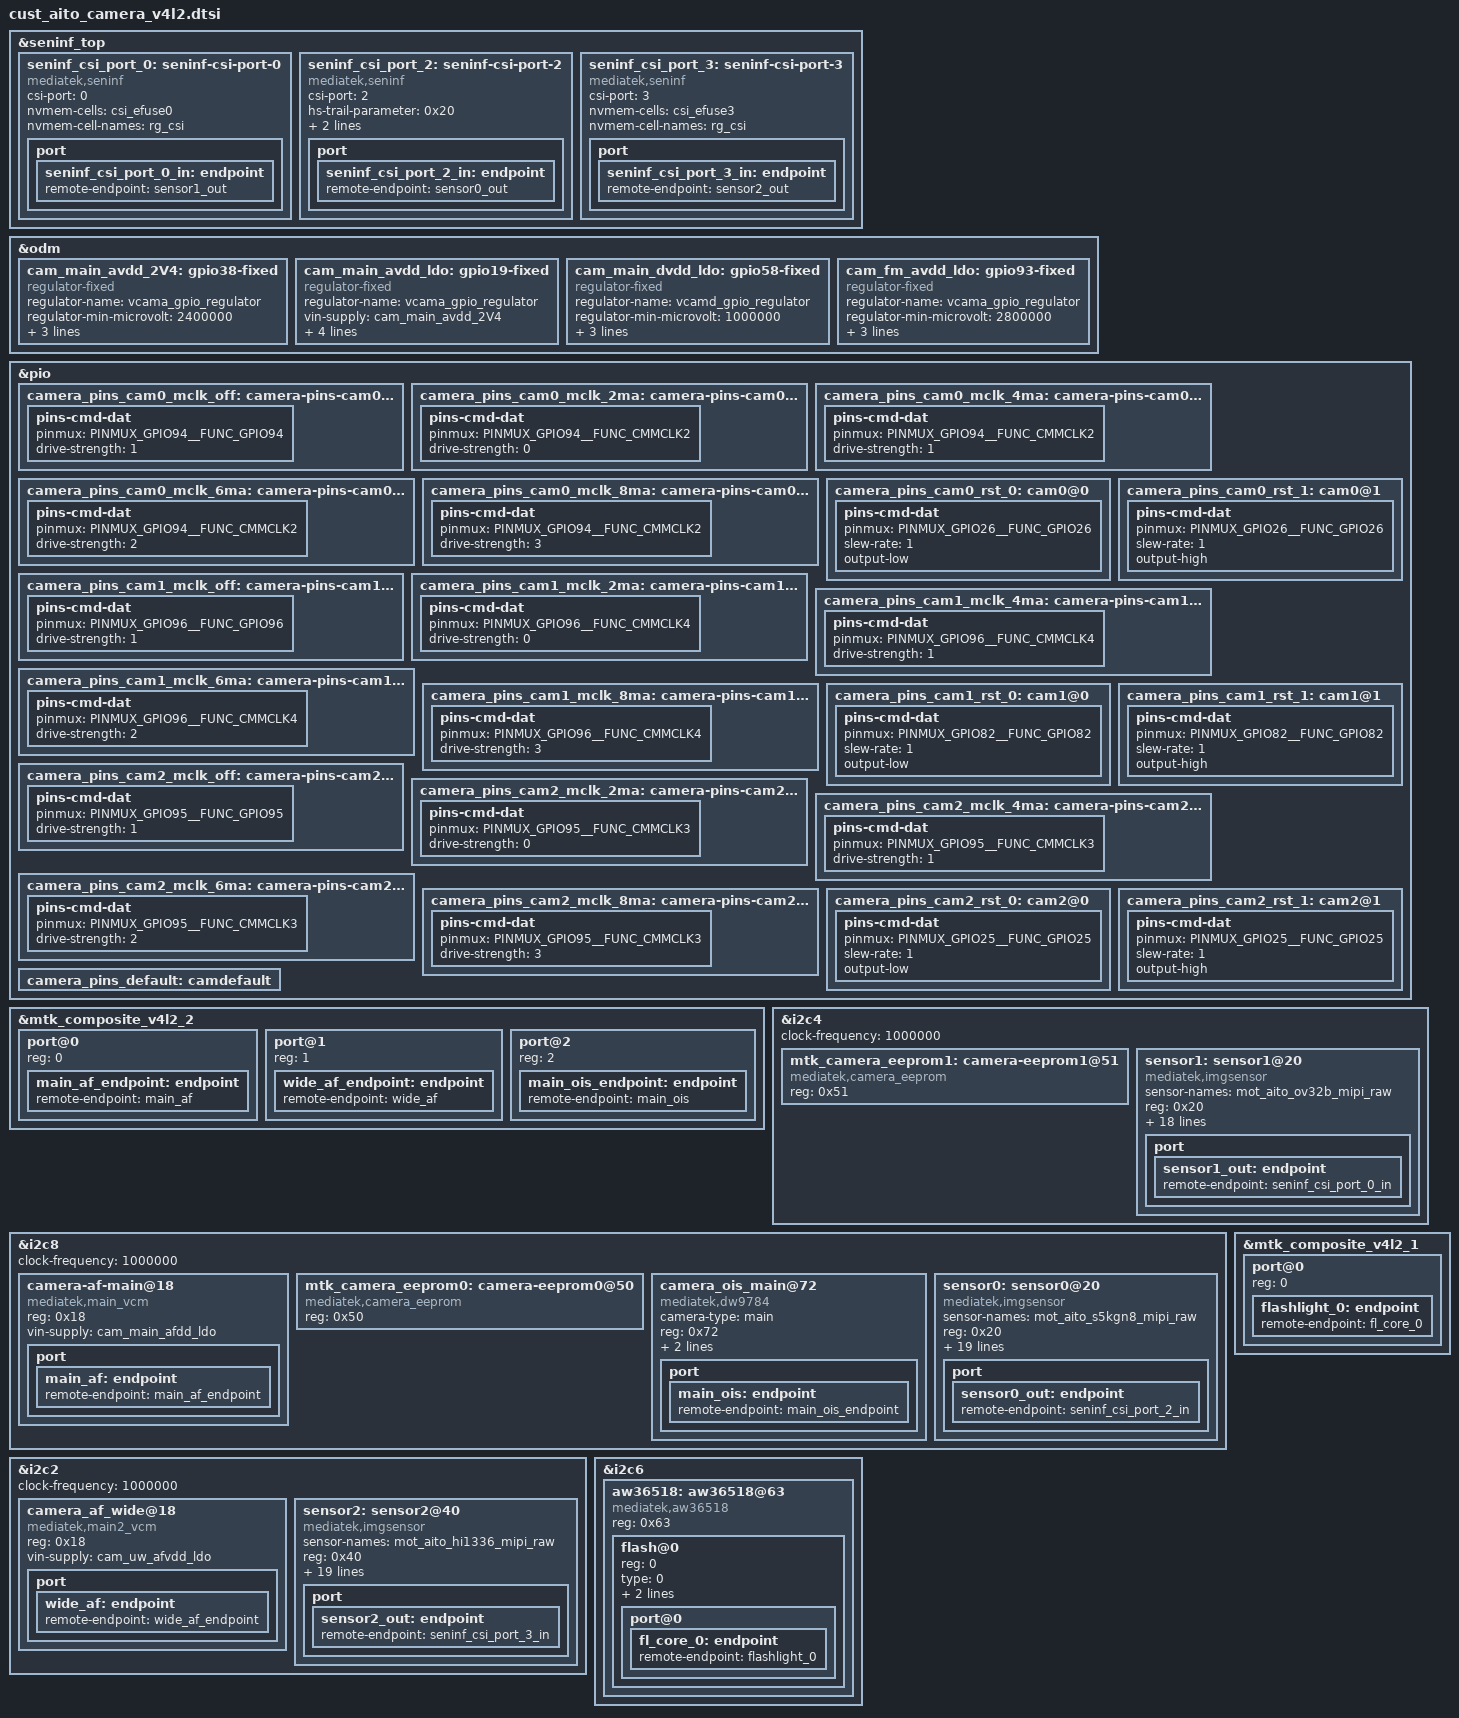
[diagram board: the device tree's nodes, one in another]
// SPDX-License-Identifier: GPL-2.0
/* Copyright (c) 2020 MediaTek Inc. */
#include <dt-bindings/clock/mt6878-clk.h>

&seninf_top {
		seninf_csi_port_0: seninf-csi-port-0 {
			compatible = "mediatek,seninf";
			csi-port = "0";
			nvmem-cells = <&csi_efuse0>;
			nvmem-cell-names = "rg_csi";
			port {
				seninf_csi_port_0_in: endpoint {
					remote-endpoint = <&sensor1_out>;
				};
			};
		};

		seninf_csi_port_2: seninf-csi-port-2 {
			compatible = "mediatek,seninf";
			csi-port = "2";
			hs-trail-parameter = <0x20>;
			nvmem-cells = <&csi_efuse2>;
			nvmem-cell-names = "rg_csi";
			port {
				seninf_csi_port_2_in: endpoint {
					remote-endpoint = <&sensor0_out>;
				};
			};
		};
		seninf_csi_port_3: seninf-csi-port-3 {
			compatible = "mediatek,seninf";
			csi-port = "3";
			nvmem-cells = <&csi_efuse3>;
			nvmem-cell-names = "rg_csi";
			port {
				seninf_csi_port_3_in: endpoint {
					remote-endpoint = <&sensor2_out>;
				};
			};
		};
};

/* CAMERA GPIO fixed to regulator */
&odm {
	cam_main_avdd_2V4: gpio38-fixed {
		compatible = "regulator-fixed";
		regulator-name = "vcama_gpio_regulator";
		regulator-min-microvolt = <2400000>;
		regulator-max-microvolt = <2400000>;
		enable-active-high;
		gpio = <&pio 38 0x0>;
	};
	cam_main_avdd_ldo: gpio19-fixed {
		compatible = "regulator-fixed";
		regulator-name = "vcama_gpio_regulator";
		vin-supply = <&cam_main_avdd_2V4>;
		regulator-min-microvolt = <2200000>;
		regulator-max-microvolt = <2200000>;
		enable-active-high;
		gpio = <&pio 19 0x0>;
	};

	cam_main_dvdd_ldo: gpio58-fixed {
		compatible = "regulator-fixed";
		regulator-name = "vcamd_gpio_regulator";
		regulator-min-microvolt = <1000000>;
		regulator-max-microvolt = <1000000>;
		enable-active-high;
		gpio = <&pio 58 0x0>;
	};
	cam_fm_avdd_ldo: gpio93-fixed {
		compatible = "regulator-fixed";
		regulator-name = "vcama_gpio_regulator";
		regulator-min-microvolt = <2800000>;
		regulator-max-microvolt = <2800000>;
		enable-active-high;
		gpio = <&pio 93 0x0>;
	};
};

/* CAMERA GPIO standardization */
&pio {
	camera_pins_cam0_mclk_off: camera-pins-cam0-mclk-off {
		pins-cmd-dat {
			pinmux = <PINMUX_GPIO94__FUNC_GPIO94>;
			drive-strength = <1>;
		};
	};
	camera_pins_cam0_mclk_2ma: camera-pins-cam0-mclk-2ma {
		pins-cmd-dat {
			pinmux = <PINMUX_GPIO94__FUNC_CMMCLK2>;
			drive-strength = <0>;
		};
	};
	camera_pins_cam0_mclk_4ma: camera-pins-cam0-mclk-4ma {
		pins-cmd-dat {
			pinmux = <PINMUX_GPIO94__FUNC_CMMCLK2>;
			drive-strength = <1>;
		};
	};
	camera_pins_cam0_mclk_6ma: camera-pins-cam0-mclk-6ma {
		pins-cmd-dat {
			pinmux = <PINMUX_GPIO94__FUNC_CMMCLK2>;
			drive-strength = <2>;
		};
	};
	camera_pins_cam0_mclk_8ma: camera-pins-cam0-mclk-8ma {
		pins-cmd-dat {
			pinmux = <PINMUX_GPIO94__FUNC_CMMCLK2>;
			drive-strength = <3>;
		};
	};
	camera_pins_cam0_rst_0: cam0@0 {
		pins-cmd-dat {
			pinmux = <PINMUX_GPIO26__FUNC_GPIO26>;
			slew-rate = <1>;
			output-low;
		};
	};
	camera_pins_cam0_rst_1: cam0@1 {
		pins-cmd-dat {
			pinmux = <PINMUX_GPIO26__FUNC_GPIO26>;
			slew-rate = <1>;
			output-high;
		};
	};

	camera_pins_cam1_mclk_off: camera-pins-cam1-mclk-off {
		pins-cmd-dat {
			pinmux = <PINMUX_GPIO96__FUNC_GPIO96>;
			drive-strength = <1>;
		};
	};
	camera_pins_cam1_mclk_2ma: camera-pins-cam1-mclk-2ma {
		pins-cmd-dat {
			pinmux = <PINMUX_GPIO96__FUNC_CMMCLK4>;
			drive-strength = <0>;
		};
	};
	camera_pins_cam1_mclk_4ma: camera-pins-cam1-mclk-4ma {
		pins-cmd-dat {
			pinmux = <PINMUX_GPIO96__FUNC_CMMCLK4>;
			drive-strength = <1>;
		};
	};
	camera_pins_cam1_mclk_6ma: camera-pins-cam1-mclk-6ma {
		pins-cmd-dat {
			pinmux = <PINMUX_GPIO96__FUNC_CMMCLK4>;
			drive-strength = <2>;
		};
	};
	camera_pins_cam1_mclk_8ma: camera-pins-cam1-mclk-8ma {
		pins-cmd-dat {
			pinmux = <PINMUX_GPIO96__FUNC_CMMCLK4>;
			drive-strength = <3>;
		};
	};
	camera_pins_cam1_rst_0: cam1@0 {
		pins-cmd-dat {
			pinmux = <PINMUX_GPIO82__FUNC_GPIO82>;
			slew-rate = <1>;
			output-low;
		};
	};
	camera_pins_cam1_rst_1: cam1@1 {
		pins-cmd-dat {
			pinmux = <PINMUX_GPIO82__FUNC_GPIO82>;
			slew-rate = <1>;
			output-high;
		};
	};

	camera_pins_cam2_mclk_off: camera-pins-cam2-mclk-off {
		pins-cmd-dat {
			pinmux = <PINMUX_GPIO95__FUNC_GPIO95>;
			drive-strength = <1>;
		};
	};
	camera_pins_cam2_mclk_2ma: camera-pins-cam2-mclk-2ma {
		pins-cmd-dat {
			pinmux = <PINMUX_GPIO95__FUNC_CMMCLK3>;
			drive-strength = <0>;
		};
	};
	camera_pins_cam2_mclk_4ma: camera-pins-cam2-mclk-4ma {
		pins-cmd-dat {
			pinmux = <PINMUX_GPIO95__FUNC_CMMCLK3>;
			drive-strength = <1>;
		};
	};
	camera_pins_cam2_mclk_6ma: camera-pins-cam2-mclk-6ma {
		pins-cmd-dat {
			pinmux = <PINMUX_GPIO95__FUNC_CMMCLK3>;
			drive-strength = <2>;
		};
	};
	camera_pins_cam2_mclk_8ma: camera-pins-cam2-mclk-8ma {
		pins-cmd-dat {
			pinmux = <PINMUX_GPIO95__FUNC_CMMCLK3>;
			drive-strength = <3>;
		};
	};
	camera_pins_cam2_rst_0: cam2@0 {
		pins-cmd-dat {
			pinmux = <PINMUX_GPIO25__FUNC_GPIO25>;
			slew-rate = <1>;
			output-low;
		};
	};
	camera_pins_cam2_rst_1: cam2@1 {
		pins-cmd-dat {
			pinmux = <PINMUX_GPIO25__FUNC_GPIO25>;
			slew-rate = <1>;
			output-high;
		};
	};
	camera_pins_default: camdefault {
	};
};
/* CAMERA GPIO end */

&mtk_composite_v4l2_2 {



	#address-cells = <1>;
	#size-cells = <0>;
	port@0 {
		reg = <0>;
		main_af_endpoint: endpoint {
			remote-endpoint = <&main_af>;
		};
	};
	port@1 {
		reg = <1>;
		wide_af_endpoint: endpoint {
			remote-endpoint = <&wide_af>;
		};
	};
	port@2 {
		reg = <2>;
		main_ois_endpoint: endpoint {
			remote-endpoint = <&main_ois>;
		};
	};
};

&i2c4 {
	status = "okay";
	clock-frequency = <1000000>;

	mtk_camera_eeprom1:camera-eeprom1@51 {
		compatible = "mediatek,camera_eeprom";
		reg = <0x51>;
		status = "okay";
	};

	sensor1: sensor1@20 {
		compatible = "mediatek,imgsensor";
		sensor-names = "mot_aito_ov32b_mipi_raw";
		reg = <0x20>;

		#thermal-sensor-cells = <0>;

		pinctrl-names = "mclk_off",
				"mclk_2mA",
				"mclk_4mA",
				"mclk_6mA",
				"mclk_8mA",
				"rst_low",
				"rst_high";
		pinctrl-0 = <&camera_pins_cam1_mclk_off>;
		pinctrl-1 = <&camera_pins_cam1_mclk_2ma>;
		pinctrl-2 = <&camera_pins_cam1_mclk_4ma>;
		pinctrl-3 = <&camera_pins_cam1_mclk_6ma>;
		pinctrl-4 = <&camera_pins_cam1_mclk_8ma>;
		pinctrl-5 = <&camera_pins_cam1_rst_0>;
		pinctrl-6 = <&camera_pins_cam1_rst_1>;

		dvdd-supply = <&cam_fm_dvdd_ldo>;
		avdd-supply = <&cam_fm_avdd_ldo>;
		dovdd-supply = <&cam_iovdd_ldo>;

		clocks = <&topckgen_clk CLK_TOP_UVPLL192M_D32>,
			<&topckgen_clk CLK_TOP_UVPLL192M_D16>,
			<&topckgen_clk CLK_TOP_OSC_D20>,
			<&topckgen_clk CLK_TOP_UVPLL192M_D10>,
			<&topckgen_clk CLK_TOP_UVPLL192M_D8>,
			<&topckgen_clk CLK_TOP_TCK_26M_MX9>,
			<&topckgen_clk CLK_TOP_UNIVPLL_D6_D8>,
			<&topckgen_clk CLK_TOP_CAMTG5_SEL>;
		clock-names = "6", "12", "13", "19.2", "24", "26", "52", "mclk";

		status = "okay";
		port {
			sensor1_out: endpoint {
				remote-endpoint = <&seninf_csi_port_0_in>;
			};
		};
	};
};


&i2c8 {
	status = "okay";
	clock-frequency = <1000000>;

	camera-af-main@18 {
		compatible = "mediatek,main_vcm";
		reg = <0x18>;
		vin-supply = <&cam_main_afdd_ldo>;
		port {
			main_af: endpoint {
				remote-endpoint = <&main_af_endpoint>;
			};
		};
	};

	mtk_camera_eeprom0:camera-eeprom0@50 {
		compatible = "mediatek,camera_eeprom";
		reg = <0x50>;
		status = "okay";
	};

	camera_ois_main@72 {
		compatible = "mediatek,dw9784";
		camera-type = "main";
		reg = <0x72>;
		vin-supply = <&cam_main_afdd_ldo>;
		vdd-supply = <&cam_main_ois_vdd_ldo>;
		status = "okay";
		port {
			main_ois: endpoint {
			remote-endpoint = <&main_ois_endpoint>;
			};
		};
	};

	sensor0: sensor0@20 {
		compatible = "mediatek,imgsensor";
		sensor-names = "mot_aito_s5kgn8_mipi_raw";
		reg = <0x20>;

		#thermal-sensor-cells = <0>;

		pinctrl-names = "mclk_off",
				"mclk_2mA",
				"mclk_4mA",
				"mclk_6mA",
				"mclk_8mA",
				"rst_low",
				"rst_high";
		pinctrl-0 = <&camera_pins_cam0_mclk_off>;
		pinctrl-1 = <&camera_pins_cam0_mclk_2ma>;
		pinctrl-2 = <&camera_pins_cam0_mclk_4ma>;
		pinctrl-3 = <&camera_pins_cam0_mclk_6ma>;
		pinctrl-4 = <&camera_pins_cam0_mclk_8ma>;
		pinctrl-5 = <&camera_pins_cam0_rst_0>;
		pinctrl-6 = <&camera_pins_cam0_rst_1>;

		avdd-supply = <&cam_main_avdd_ldo>;
		afvdd1-supply = <&cam_main_afdd_ldo>;
		dovdd-supply = <&cam_iovdd_ldo>;
		dvdd-supply = <&cam_main_dvdd_ldo>;


		clocks = <&topckgen_clk CLK_TOP_UVPLL192M_D32>,
			<&topckgen_clk CLK_TOP_UVPLL192M_D16>,
			<&topckgen_clk CLK_TOP_OSC_D20>,
			<&topckgen_clk CLK_TOP_UVPLL192M_D10>,
			<&topckgen_clk CLK_TOP_UVPLL192M_D8>,
			<&topckgen_clk CLK_TOP_TCK_26M_MX9>,
			<&topckgen_clk CLK_TOP_UNIVPLL_D6_D8>,
			<&topckgen_clk CLK_TOP_CAMTG3_SEL>;
		clock-names = "6", "12", "13", "19.2", "24", "26", "52", "mclk";


		status = "okay";
		port {
			sensor0_out: endpoint {
				remote-endpoint = <&seninf_csi_port_2_in>;
			};
		};
	};
};

&i2c2 {
	status = "okay";
	clock-frequency = <1000000>;

	camera_af_wide@18 {
		compatible = "mediatek,main2_vcm";
		reg = <0x18>;
		vin-supply = <&cam_uw_afvdd_ldo>;
		port {
			wide_af: endpoint {
				remote-endpoint = <&wide_af_endpoint>;
			};
		};
	};

#if 0
	camera-af-main-four@d {
		compatible = "mediatek,main4_vcm";
		reg = <0x0d>;
		vin-supply = <&rt5133_ldo2>;
		port {
			main_af_cam2: endpoint {
				remote-endpoint = <&main_af_cam2_endpoint>;
			};
		};
	};

	mtk_camera_eeprom2:camera-eeprom2@50 {
		compatible = "mediatek,camera_eeprom";
		reg = <0x50>;
		status = "okay";
	};
#endif
	sensor2: sensor2@40 {
		compatible = "mediatek,imgsensor";
		sensor-names = "mot_aito_hi1336_mipi_raw";
		reg = <0x40>;
		#thermal-sensor-cells = <0>;

		pinctrl-names = "mclk_off",
				"mclk_2mA",
				"mclk_4mA",
				"mclk_6mA",
				"mclk_8mA",
				"rst_low",
				"rst_high";

		pinctrl-0 = <&camera_pins_cam2_mclk_off>;
		pinctrl-1 = <&camera_pins_cam2_mclk_2ma>;
		pinctrl-2 = <&camera_pins_cam2_mclk_4ma>;
		pinctrl-3 = <&camera_pins_cam2_mclk_6ma>;
		pinctrl-4 = <&camera_pins_cam2_mclk_8ma>;
		pinctrl-5 = <&camera_pins_cam2_rst_0>;
		pinctrl-6 = <&camera_pins_cam2_rst_1>;

		avdd-supply = <&cam_uw_avdd_ldo>;
		afvdd-supply = <&cam_uw_afvdd_ldo>;
		dovdd-supply = <&cam_iovdd_ldo>;
		dvdd-supply = <&cam_uw_dvdd_ldo>;


		clocks = <&topckgen_clk CLK_TOP_UVPLL192M_D32>,
			<&topckgen_clk CLK_TOP_UVPLL192M_D16>,
			<&topckgen_clk CLK_TOP_OSC_D20>,
			<&topckgen_clk CLK_TOP_UVPLL192M_D10>,
			<&topckgen_clk CLK_TOP_UVPLL192M_D8>,
			<&topckgen_clk CLK_TOP_TCK_26M_MX9>,
			<&topckgen_clk CLK_TOP_UNIVPLL_D6_D8>,
			<&topckgen_clk CLK_TOP_CAMTG4_SEL>;
		clock-names = "6", "12", "13", "19.2", "24", "26", "52", "mclk";

		status = "okay";
		port {
			sensor2_out: endpoint {
				remote-endpoint = <&seninf_csi_port_3_in>;
			};
		};
	};
};

&i2c6 {
	aw36518:aw36518@63 {
		compatible = "mediatek,aw36518";
		reg = <0x63>;
		#cooling-cells = <2>;
		status = "okay";
		flash@0{
			reg = <0>;
			type = <0>;
			ct = <0>;
			part = <0>;
			port@0 {
				fl_core_0: endpoint {
					remote-endpoint = <&flashlight_0>;
				};
			};
		};
	};
};


&mtk_composite_v4l2_1 {
	#address-cells = <1>;
	#size-cells = <0>;
	port@0 {
		reg = <0>;
		flashlight_0: endpoint {
			remote-endpoint = <&fl_core_0>;
		};
	};
};
